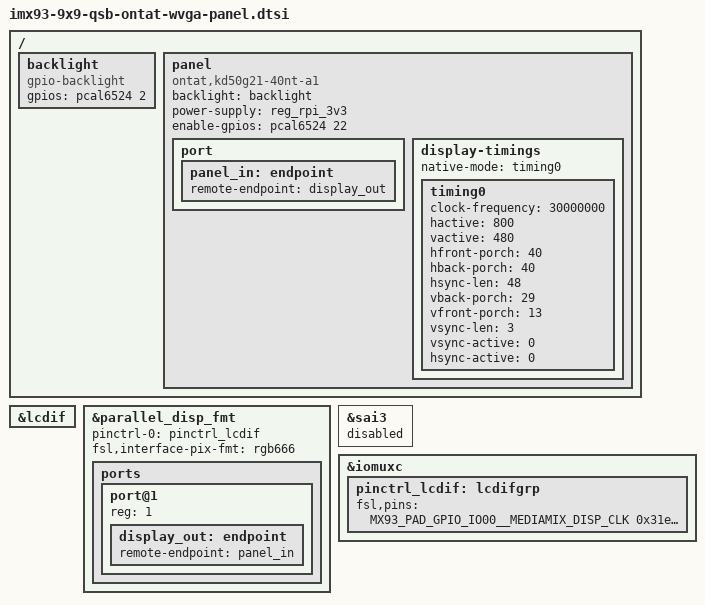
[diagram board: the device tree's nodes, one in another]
// SPDX-License-Identifier: (GPL-2.0+ OR MIT)
/*
 * Copyright 2022 NXP
 */


/ {
	backlight: backlight {
		compatible = "gpio-backlight";
		gpios = <&pcal6524 2 GPIO_ACTIVE_HIGH>;
	};

	panel {
		compatible = "ontat,kd50g21-40nt-a1", "simple-panel";
		backlight = <&backlight>;
		power-supply = <&reg_rpi_3v3>;
		enable-gpios = <&pcal6524 22 GPIO_ACTIVE_HIGH>;

		port {
			panel_in: endpoint {
				remote-endpoint = <&display_out>;
			};
		};

		display-timings {
			native-mode = <&timing0>;
			timing0: timing0 {
				clock-frequency = <30000000>;
				hactive = <800>;
				vactive = <480>;
				hfront-porch = <40>;
				hback-porch = <40>;
				hsync-len = <48>;
				vback-porch = <29>;
				vfront-porch = <13>;
				vsync-len = <3>;

				vsync-active = <0>;
				hsync-active = <0>;
			};
		};
	};
};

&lcdif {
	status = "okay";
	/*assigned-clock-rates = <150000000>, <30000000>, <400000000>, <133333333>;*/
};

&parallel_disp_fmt {
	pinctrl-names = "default";
	pinctrl-0 = <&pinctrl_lcdif>;
	fsl,interface-pix-fmt = "rgb666";
	status = "okay";

	ports {
		port@1 {
			reg = <1>;

			display_out: endpoint {
				remote-endpoint = <&panel_in>;
			};
		};
	};
};

/* pin conflicts */
&sai3 {
	status = "disabled";
};

&iomuxc {
	pinctrl_lcdif: lcdifgrp {
		fsl,pins = <
			MX93_PAD_GPIO_IO00__MEDIAMIX_DISP_CLK           0x31e
			MX93_PAD_GPIO_IO01__MEDIAMIX_DISP_DE            0x31e
			MX93_PAD_GPIO_IO02__MEDIAMIX_DISP_VSYNC         0x31e
			MX93_PAD_GPIO_IO03__MEDIAMIX_DISP_HSYNC         0x31e
			MX93_PAD_GPIO_IO04__MEDIAMIX_DISP_DATA00        0x31e
			MX93_PAD_GPIO_IO05__MEDIAMIX_DISP_DATA01        0x31e
			MX93_PAD_GPIO_IO06__MEDIAMIX_DISP_DATA02        0x31e
			MX93_PAD_GPIO_IO07__MEDIAMIX_DISP_DATA03        0x31e
			MX93_PAD_GPIO_IO08__MEDIAMIX_DISP_DATA04        0x31e
			MX93_PAD_GPIO_IO09__MEDIAMIX_DISP_DATA05        0x31e
			MX93_PAD_GPIO_IO10__MEDIAMIX_DISP_DATA06        0x31e
			MX93_PAD_GPIO_IO11__MEDIAMIX_DISP_DATA07        0x31e
			MX93_PAD_GPIO_IO12__MEDIAMIX_DISP_DATA08        0x31e
			MX93_PAD_GPIO_IO13__MEDIAMIX_DISP_DATA09        0x31e
			MX93_PAD_GPIO_IO14__MEDIAMIX_DISP_DATA10        0x31e
			MX93_PAD_GPIO_IO15__MEDIAMIX_DISP_DATA11        0x31e
			MX93_PAD_GPIO_IO16__MEDIAMIX_DISP_DATA12        0x31e
			MX93_PAD_GPIO_IO17__MEDIAMIX_DISP_DATA13        0x31e
			MX93_PAD_GPIO_IO18__MEDIAMIX_DISP_DATA14        0x31e
			MX93_PAD_GPIO_IO19__MEDIAMIX_DISP_DATA15        0x31e
			MX93_PAD_GPIO_IO20__MEDIAMIX_DISP_DATA16        0x31e
			MX93_PAD_GPIO_IO21__MEDIAMIX_DISP_DATA17        0x31e
		>;
	};
};
